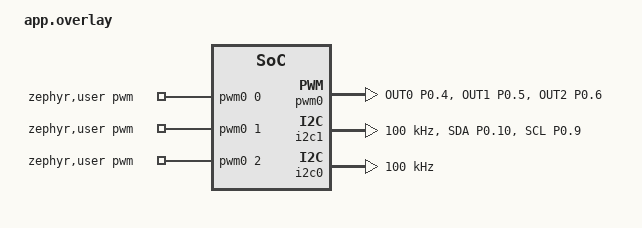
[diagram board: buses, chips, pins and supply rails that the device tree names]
/*
 * PoC v1 보드(nRF52832-QFAA-R) 전용 devicetree overlay.
 * 근거: pinmap.md §3 — P0.09/P0.10이 NIR1 I2C(SCL/SDA)로 실장되어 있어
 * NFC 안테나 전용 핀 기본값을 포기하고 GPIO로 전환해야 한다.
 *
 * 이 NCS 버전(Zephyr 4.4)은 CONFIG_NFCT_PINS_AS_GPIOS Kconfig가 폐지되었고
 * 대신 UICR devicetree 프로퍼티로 설정한다 (zephyr migration-guide-3.5.rst 참고).
 */
#include <zephyr/dt-bindings/pinctrl/nrf-pinctrl.h>
#include <zephyr/dt-bindings/pwm/pwm.h>
#include <zephyr/dt-bindings/i2c/i2c.h>

&uicr {
	nfct-pins-as-gpios;
};

/*
 * 2026-09-15 근본 원인 발견: nrf52dk/nrf52832 "보드"(우리가 PoC v1 대신 빌드용으로
 * 쓰는 표준 DK 정의)의 기본 devicetree가 UART0을 활성화하고, 그 기본 핀 배정이
 * UART_TX=P0.06(D4), UART_RTS=P0.05(D3)이다 — 즉 PWM0과 UART0이 같은 물리 핀을
 * 동시에 차지하려고 경합하고 있었다. CONFIG_LOG_BACKEND_UART=n은 로깅 서브시스템의
 * 백엔드만 끄고, UART0 페리페럴/핀컨트롤 자체는 계속 활성 상태였다.
 * P0.04(D2)는 UART가 안 쓰는 핀이라 이 경합이 없어서 정상 동작했던 것 — D3/D4가
 * "하드웨어 결함"처럼 보였던 진짜 원인이다 (하드웨어 문제 아님, 결론 정정).
 * PoC v1 실제 보드는 UART 핀이 노출되어 있지 않으므로(pinmap.md §4) UART0을 아예
 * 비활성화한다.
 */
&uart0 {
	status = "disabled";
};

/*
 * LED PWM (pinmap.md §2): LED1(640nm)=P0.04, LED2(680nm)=P0.05, LED3(PoC v1
 * 실장 980nm, 스펙 950nm)=P0.06. 전부 PWM0의 채널 0/1/2로 묶는다.
 * NPN 트랜지스터 베이스 직결(R17~R20=0Ω) 구조라 GPIO High = LED ON (active-high,
 * nordic,invert 불필요) — pinmap.md §2 회로 그대로.
 */
&pinctrl {
	pwm0_default: pwm0_default {
		group1 {
			psels = <NRF_PSEL(PWM_OUT0, 0, 4)>,
				<NRF_PSEL(PWM_OUT1, 0, 5)>,
				<NRF_PSEL(PWM_OUT2, 0, 6)>;
			/* nrf52dk_nrf52832-pinctrl.dtsi의 원래 pwm0_default(핀17, 온보드 LED)에는
			 * nordic,invert가 있다 — 우리 회로는 active-high라 반드시 제거해야 한다.
			 * (2026-09-14: 실기 검증 중 채널0만 반전되는 걸 발견해 추가.)
			 */
			/delete-property/ nordic,invert;
		};
	};

	pwm0_sleep: pwm0_sleep {
		group1 {
			psels = <NRF_PSEL(PWM_OUT0, 0, 4)>,
				<NRF_PSEL(PWM_OUT1, 0, 5)>,
				<NRF_PSEL(PWM_OUT2, 0, 6)>;
			low-power-enable;
		};
	};
};

&pwm0 {
	status = "okay";
	pinctrl-0 = <&pwm0_default>;
	pinctrl-1 = <&pwm0_sleep>;
	pinctrl-names = "default", "sleep";
};

/* m_i2c_led.c가 PWM_DT_SPEC_GET_BY_IDX(DT_PATH(zephyr_user), N)으로 참조한다.
 * 인덱스 순서는 config_app.h의 nirs_wavelength_t(640/680/950nm) 순서와 일치해야 한다.
 * TODO(open-item): PWM 주파수(현재 1kHz, 1ms 주기)는 임시값 — Rev1 AS7341 실측 시
 * integration time과의 상호작용을 보고 재조정한다.
 *
 * 2026-09-15 채널 스왑 진단: index0<->index2를 바꿔도 "잘 되는 LED"는 계속 P0.04(D2)를
 * 따라갔고 P0.05(D3)/P0.06(D4)는 계속 고장 — 당시엔 하드웨어 결함으로 오판했으나,
 * 실제 원인은 위 &uart0 경합이었다 (pinmap.md §8 참고). 원래 순서(0,1,2)로 복귀.
 */
/ {
	zephyr,user {
		pwms = <&pwm0 0 PWM_USEC(1000) PWM_POLARITY_NORMAL>,
		       <&pwm0 1 PWM_USEC(1000) PWM_POLARITY_NORMAL>,
		       <&pwm0 2 PWM_USEC(1000) PWM_POLARITY_NORMAL>;
	};
};

/*
 * NIR1 AS7341 I2C (pinmap.md §3): SCL=P0.09(NFC1, 위 UICR로 이미 GPIO 전환됨),
 * SDA=P0.10(NFC2). nRF52832의 I2C1(TWIM1) 인스턴스를 사용한다.
 * NIR2(SCL=P0.08, SDA=P0.07)는 I2C0으로 이어서 추가할 예정 (오늘은 NIR1만 우선 검증).
 * 풀업(R3/R4=4.7kΩ)이 보드에 이미 실장되어 있어 내부 풀업은 켜지 않는다.
 */
&pinctrl {
	i2c1_default: i2c1_default {
		group1 {
			psels = <NRF_PSEL(TWIM_SDA, 0, 10)>,
				<NRF_PSEL(TWIM_SCL, 0, 9)>;
		};
	};

	i2c1_sleep: i2c1_sleep {
		group1 {
			psels = <NRF_PSEL(TWIM_SDA, 0, 10)>,
				<NRF_PSEL(TWIM_SCL, 0, 9)>;
			low-power-enable;
		};
	};
};

&i2c1 {
	compatible = "nordic,nrf-twim";
	status = "okay";
	pinctrl-0 = <&i2c1_default>;
	pinctrl-1 = <&i2c1_sleep>;
	pinctrl-names = "default", "sleep";
	clock-frequency = <I2C_BITRATE_STANDARD>;

	/* AS7341 SMUX RAM 쓰기는 레지스터주소(1) + 데이터(20) = 21바이트를 burst write
	 * 한다. 드라이버 기본 내부 버퍼(16바이트)를 넘어서 실기에서 -ENOSPC(-28)로
	 * 실패하는 걸 확인해서 늘렸다 (2026-09-15, i2c_nrfx_twim 에러 로그로 확인).
	 */
	zephyr,concat-buf-size = <32>;
};

/*
 * NIR2 AS7341 I2C (pinmap.md §3): SCL=P0.08, SDA=P0.07, I2C0(TWIM0) 사용.
 * nrf52dk 기본 devicetree는 i2c0(arduino_i2c)을 이미 status="okay"로 P0.26/P0.27에
 * 연결해뒀다 — 같은 라벨(i2c0_default/i2c0_sleep)의 psels를 우리 핀으로 덮어쓴다
 * (&uart0 disable과 별개로, P0.07/P0.08은 UART0의 CTS/RX 기본 핀과 겹치지만 UART0을
 * 이미 비활성화했으므로 경합 없음 — pinmap.md §8 교훈 참고).
 */
&pinctrl {
	i2c0_default: i2c0_default {
		group1 {
			psels = <NRF_PSEL(TWIM_SDA, 0, 7)>,
				<NRF_PSEL(TWIM_SCL, 0, 8)>;
		};
	};

	i2c0_sleep: i2c0_sleep {
		group1 {
			psels = <NRF_PSEL(TWIM_SDA, 0, 7)>,
				<NRF_PSEL(TWIM_SCL, 0, 8)>;
			low-power-enable;
		};
	};
};

&i2c0 {
	compatible = "nordic,nrf-twim";
	status = "okay";
	clock-frequency = <I2C_BITRATE_STANDARD>;
	zephyr,concat-buf-size = <32>; /* i2c1과 동일 이유 (SMUX 21바이트 burst write) */
};
